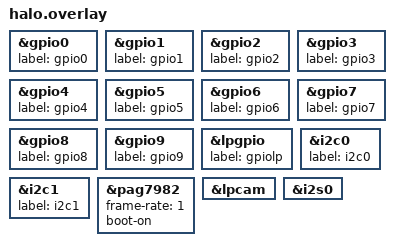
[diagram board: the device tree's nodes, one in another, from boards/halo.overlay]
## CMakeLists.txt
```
# Copyright (C) 2025 Alif Semiconductor - All Rights Reserved.
# Use, distribution and modification of this code is permitted under the
# terms stated in the Alif Semiconductor Software License Agreement
#
# You should have received a copy of the Alif Semiconductor Software
# License Agreement with this file. If not, please write to:
# contact@alifsemi.com, or visit: https://alifsemi.com/license

cmake_minimum_required(VERSION 3.20.0)
find_package(Zephyr REQUIRED HINTS $ENV{ZEPHYR_BASE})
project(le_throughput)

set(sources
    src/main.c
)

add_subdirectory_ifdef(CONFIG_ALIF_THROUHGPUT_SHELL shell/)

target_sources(app PRIVATE ${sources})
```

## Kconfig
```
# Copyright (C) 2025 Alif Semiconductor - All Rights Reserved.
# Use, distribution and modification of this code is permitted under the
# terms stated in the Alif Semiconductor Software License Agreement
#
# You should have received a copy of the Alif Semiconductor Software
# License Agreement with this file. If not, please write to:
# contact@alifsemi.com, or visit: https://alifsemi.com/license

menu "Alif Bluetooth LE Throughput"

config ALIF_THROUHGPUT_SHELL
	bool "Bluetooth throughput commands"
	default y

config BLE_BONDING
	bool "Bond to peripheral"

config BLE_THROUGHPUT_DURATION
	int "Throughput test duration in milliseconds"
	default 20000

config BLE_MTU_SIZE
	int "MTU to be used for throughput testing"
	range 23 517
	default 498

config BLE_TP_DEVICE_NAME
	string "Default BLE throughput device name"
	default "ALIF-TP"

config BLE_TP_BIDIRECTIONAL_TEST
	bool "Bidirectional throughput test"
	default y

config ALIF_TP_SHELL_THREAD_PRIORITY
	int "Priority for thread running the throughput"
	default 0

config ALIF_TP_SHELL_THREAD_STACKSIZE
	int "Stack size for thread running the throughput"
	default 2048

endmenu # "Alif Bluetooth LE Throughput"

source "Kconfig.zephyr"
```

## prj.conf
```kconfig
CONFIG_BT=y
CONFIG_BT_CUSTOM=y
CONFIG_LOG=y
CONFIG_ASSERT=y
CONFIG_GPIO=y
CONFIG_SHELL=y

CONFIG_HEAP_MEM_POOL_SIZE=4096
CONFIG_MAIN_STACK_SIZE=4096
CONFIG_IDLE_STACK_SIZE=4096
CONFIG_ISR_STACK_SIZE=4096
CONFIG_ALIF_BLE_HOST_ADDL_PRF_HEAPSIZE=10240
CONFIG_ALIF_BLE_HOST_ADDL_ENV_HEAPSIZE=8192

CONFIG_LOG_MODE_MINIMAL=y
```

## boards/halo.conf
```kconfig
CONFIG_I2C_DW=y
CONFIG_I2C_TARGET=y
CONFIG_I2C=y
CONFIG_I2C_DW_CLOCK_SPEED=40

# Flash layout
CONFIG_XIP=y
CONFIG_FLASH=y
CONFIG_FLASH_MAP=y
CONFIG_FLASH_PAGE_LAYOUT=y
CONFIG_MPU_ALLOW_FLASH_WRITE=y
CONFIG_HEAP_MEM_POOL_SIZE=65536

# # Microphone & Speaker
# CONFIG_I2S=y
# CONFIG_AUDIO=y
# CONFIG_MAX98357A_AUDIO=y
# CONFIG_MAX98357A_AUDIO_GENERIC_API=y
# CONFIG_T5838_AAD_TRIGGER=y

# # Display
# CONFIG_DISPLAY=y
# CONFIG_CDC200=y
# CONFIG_MIPI_DSI=y
# CONFIG_CANVAS=y
# CONFIG_FB_USES_DTCM_REGION=y

# # LED
# CONFIG_PWM=y
# CONFIG_LED_PWM=y
# CONFIG_LED_INIT_PRIORITY=50

# # Camera
# CONFIG_VIDEO=y
# CONFIG_VIDEO_MIPI_CSI2_DW=n
# CONFIG_VIDEO_BUFFER_POOL_NUM_MAX=1
# CONFIG_VIDEO_BUFFER_POOL_SZ_MAX=327680
# CONFIG_FB_USES_DTCM_REGION=y
# CONFIG_MPIX=y
# CONFIG_MPIX_HEAP_SIZE=65536

# BLE
CONFIG_BT=y
CONFIG_BT_CUSTOM=y
```

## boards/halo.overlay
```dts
/* label for it */

&gpio0 {
	label = "gpio0";
};
&gpio1 {
	label = "gpio1";
};
&gpio2 {
	label = "gpio2";
};
&gpio3 {
	label = "gpio3";
};
&gpio4 {
	label = "gpio4";
};
&gpio5 {
	label = "gpio5";
};
&gpio6 {
	label = "gpio6";
};
&gpio7 {
	label = "gpio7";
};
&gpio8 {
	label = "gpio8";
};
&gpio9 {
	label = "gpio9";
};
&lpgpio {
	label = "gpiolp";
};
&i2c0{
    label = "i2c0";
};
&i2c1{
    label = "i2c1";
};


&pag7982{
	status = "okay";
	frame-rate = <1>;
	boot-on;
};

&lpcam {
	status = "okay";
};

&i2s0 {
	status = "okay";
};
```

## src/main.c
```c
/* Copyright (C) 2025 Alif Semiconductor - All Rights Reserved.
 * Use, distribution and modification of this code is permitted under the
 * terms stated in the Alif Semiconductor Software License Agreement
 *
 * You should have received a copy of the Alif Semiconductor Software
 * License Agreement with this file. If not, please write to:
 * contact@alifsemi.com, or visit: https://alifsemi.com/license
 */

#include <zephyr/kernel.h>

int main(void)
{
	while (1) {
		/* All the magic happens in shell */
		k_sleep(K_SECONDS(1));
	}

	return 0;
}
```
